VERSION ""

NS_ :

BS_:

BU_: INV BMS VCU

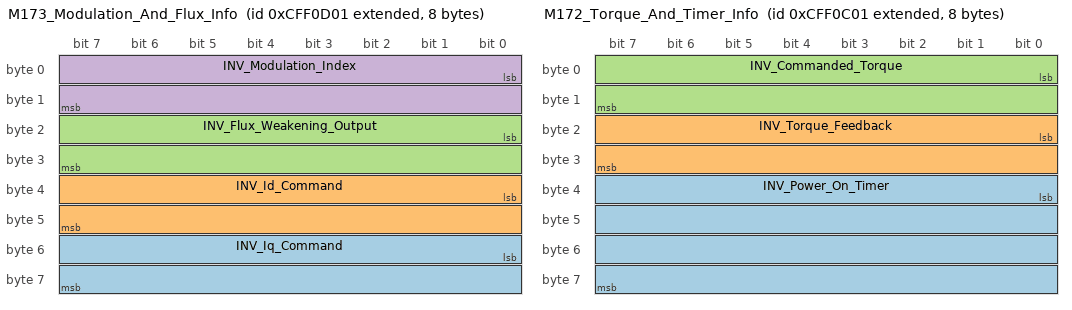
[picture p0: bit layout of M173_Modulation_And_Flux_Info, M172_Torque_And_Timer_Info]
BO_ 2365525249 M173_Modulation_And_Flux_Info: 8 INV
 SG_ INV_Iq_Command : 48|16@1- (0.1,0) [-3276.8|3276.7] "current:A" Vector__XXX
 SG_ INV_Id_Command : 32|16@1- (0.1,0) [-3276.8|3276.7] "current:A" Vector__XXX
 SG_ INV_Flux_Weakening_Output : 16|16@1- (0.1,0) [-3276.8|3276.7] "current:A" Vector__XXX
 SG_ INV_Modulation_Index : 0|16@1- (0.0001,0) [-3.2768|3.2767] "" Vector__XXX

BO_ 2365524993 M172_Torque_And_Timer_Info: 8 INV
 SG_ INV_Power_On_Timer : 32|32@1+ (0.003,0) [0|12884800] "time:second" Vector__XXX
 SG_ INV_Torque_Feedback : 16|16@1- (0.1,0) [-3276.8|3276.7] "torque:N.m" Vector__XXX
 SG_ INV_Commanded_Torque : 0|16@1- (0.1,0) [-3276.8|3276.7] "torque:N.m" Vector__XXX

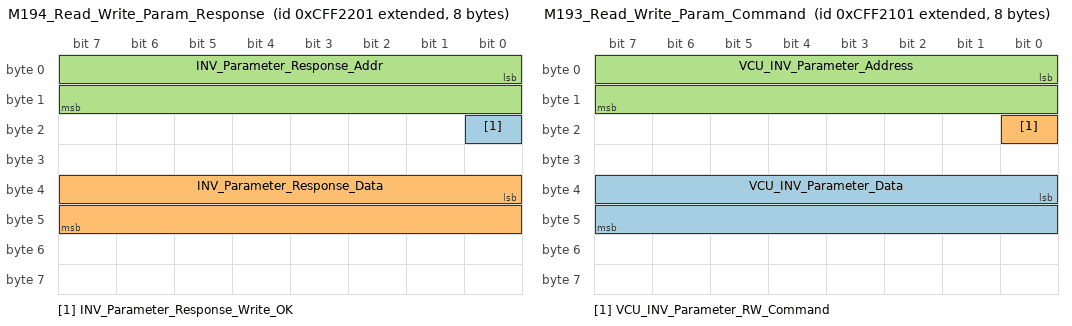
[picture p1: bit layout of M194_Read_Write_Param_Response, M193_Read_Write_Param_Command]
BO_ 2365530625 M194_Read_Write_Param_Response: 8 INV
 SG_ INV_Parameter_Response_Write_OK : 16|1@1+ (1,0) [0|1] "" Vector__XXX
 SG_ INV_Parameter_Response_Data : 32|16@1- (1,0) [-32768|32767] "" Vector__XXX
 SG_ INV_Parameter_Response_Addr : 0|16@1+ (1,0) [0|65535] "" Vector__XXX

BO_ 2365530369 M193_Read_Write_Param_Command: 8 VCU
 SG_ VCU_INV_Parameter_Data : 32|16@1- (1,0) [-32768|32767] "" Vector__XXX
 SG_ VCU_INV_Parameter_RW_Command : 16|1@1+ (1,0) [0|1] "" Vector__XXX
 SG_ VCU_INV_Parameter_Address : 0|16@1+ (1,0) [0|65535] "" Vector__XXX

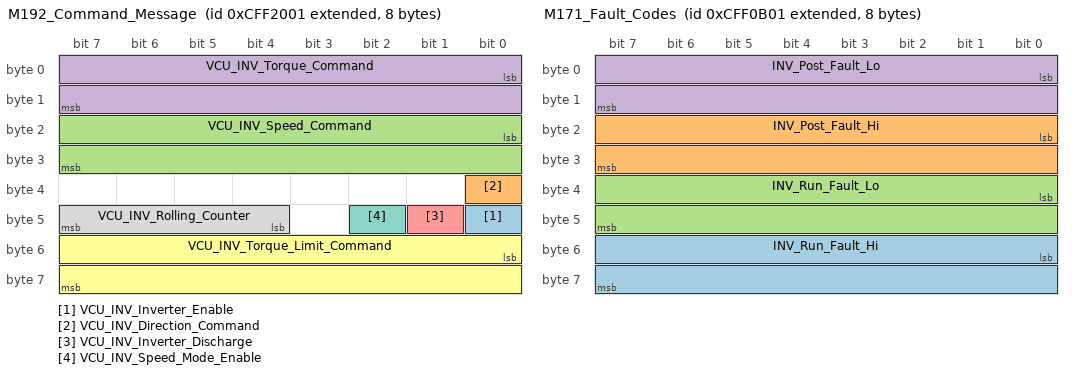
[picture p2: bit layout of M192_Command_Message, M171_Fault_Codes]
BO_ 2365530113 M192_Command_Message: 8 VCU
 SG_ VCU_INV_Inverter_Enable : 40|1@1+ (1,0) [0|1] "" Vector__XXX
 SG_ VCU_INV_Direction_Command : 32|1@1+ (1,0) [0|1] "" Vector__XXX
 SG_ VCU_INV_Speed_Command : 16|16@1- (1,0) [-32768|32767] "angular_speed:rpm" Vector__XXX
 SG_ VCU_INV_Torque_Command : 0|16@1- (0.1,0) [-3276.8|3276.7] "torque:N.m" Vector__XXX
 SG_ VCU_INV_Inverter_Discharge : 41|1@1+ (1,0) [0|1] "" Vector__XXX
 SG_ VCU_INV_Torque_Limit_Command : 48|16@1- (0.1,0) [-3276.8|3276.7] "torque:N.m" Vector__XXX
 SG_ VCU_INV_Speed_Mode_Enable : 42|1@1+ (1,0) [0|1] "" Vector__XXX
 SG_ VCU_INV_Rolling_Counter : 44|4@1+ (1,0) [0|15] "" Vector__XXX

BO_ 2365524737 M171_Fault_Codes: 8 INV
 SG_ INV_Run_Fault_Hi : 48|16@1+ (1,0) [0|65535] "" Vector__XXX
 SG_ INV_Post_Fault_Hi : 16|16@1+ (1,0) [0|65535] "" Vector__XXX
 SG_ INV_Run_Fault_Lo : 32|16@1+ (1,0) [0|65535] "" Vector__XXX
 SG_ INV_Post_Fault_Lo : 0|16@1+ (1,0) [0|65535] "" Vector__XXX

BO_ 2365524481 M170_Internal_States: 8 INV
 SG_ INV_Direction_Command : 56|1@1+ (1,0) [0|1] "" Vector__XXX
 SG_ INV_Inverter_Enable_State : 48|1@1+ (1,0) [0|1] "" Vector__XXX
 SG_ INV_Relay_3_Status : 26|1@1+ (1,0) [0|1] "" Vector__XXX
 SG_ INV_Relay_4_Status : 27|1@1+ (1,0) [0|1] "" Vector__XXX
 SG_ INV_Relay_2_Status : 25|1@1+ (1,0) [0|1] "" Vector__XXX
 SG_ INV_Inverter_Run_Mode : 32|1@1+ (1,0) [0|1] "" Vector__XXX
 SG_ INV_Inverter_Command_Mode : 40|1@1+ (1,0) [0|1] "" Vector__XXX
 SG_ INV_Relay_1_Status : 24|1@1+ (1,0) [0|1] "" Vector__XXX
 SG_ INV_Inverter_State : 16|8@1+ (1,0) [0|255] "" Vector__XXX
 SG_ INV_VSM_State : 0|8@1+ (1,0) [0|15] "" Vector__XXX
 SG_ INV_Inverter_Enable_Lockout : 55|1@1+ (1,0) [0|1] "" Vector__XXX
 SG_ INV_Inverter_Discharge_State : 37|3@1+ (1,0) [0|7] "" Vector__XXX
 SG_ INV_Relay_5_Status : 28|1@1+ (1,0) [0|1] "" Vector__XXX
 SG_ INV_Relay_6_Status : 29|1@1+ (1,0) [0|1] "" Vector__XXX
 SG_ INV_BMS_Active : 57|1@1+ (1,0) [0|1] "" Vector__XXX
 SG_ INV_BMS_Limiting_Motor_Torque : 58|1@1+ (1,0) [0|1] "" Vector__XXX
 SG_ INV_PWM_Frequency : 8|8@1+ (1,0) [0|255] "" Vector__XXX
 SG_ INV_Limit_Max_Speed : 59|1@1+ (1,0) [0|1] "" Vector__XXX
 SG_ INV_Limit_Hot_Spot_Inverter : 60|1@1+ (1,0) [0|1] "" Vector__XXX
 SG_ INV_Low_Speed_Limiting : 61|1@1+ (1,0) [0|1] "" Vector__XXX
 SG_ INV_Rolling_Counter : 44|4@1+ (1,0) [0|15] "" Vector__XXX
 SG_ INV_Limit_Coolant_Derating : 62|1@1+ (1,0) [0|1] "" Vector__XXX
 SG_ INV_Self_Sensing_Assist_Enable : 33|1@1+ (1,0) [0|1] "" Vector__XXX
 SG_ INV_Limit_Stall_Burst_Model : 63|1@1+ (1,0) [0|1] "" Vector__XXX
 SG_ INV_Burst_Model_Mode : 49|1@1+ (1,0) [0|1] "" Vector__XXX
 SG_ INV_Key_Switch_Start_Status : 54|1@1+ (1,0) [0|1] "" Vector__XXX
 SG_ INV_BMS_Limiting_Regen_Torque : 50|1@1+ (1,0) [0|0] "" Vector__XXX
 SG_ INV_Limit_Motor_Temp_Derate : 52|1@1+ (1,0) [0|0] "" Vector__XXX
 SG_ INV_Limit_Hot_Spot_Motor : 53|1@1+ (1,0) [0|0] "" Vector__XXX
 SG_ INV_ASC_State : 34|3@1+ (1,0) [0|0] "" Vector__XXX

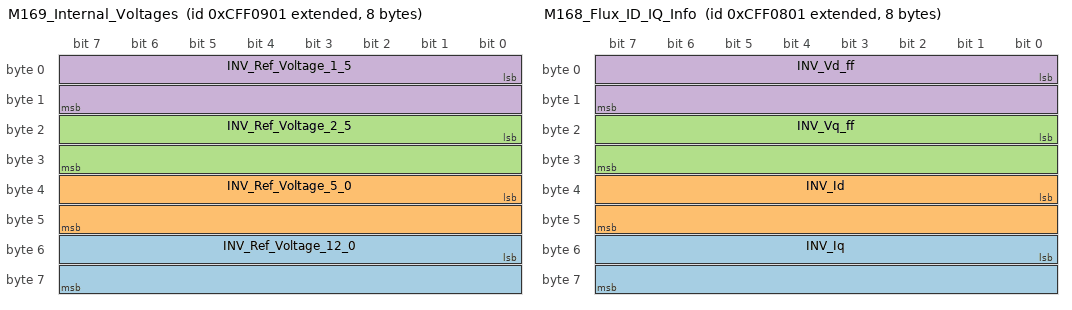
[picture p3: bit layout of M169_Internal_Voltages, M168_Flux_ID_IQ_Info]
BO_ 2365524225 M169_Internal_Voltages: 8 INV
 SG_ INV_Ref_Voltage_12_0 : 48|16@1- (0.01,0) [-327.68|327.67] "voltage:V" Vector__XXX
 SG_ INV_Ref_Voltage_5_0 : 32|16@1- (0.01,0) [-327.68|327.67] "voltage:V" Vector__XXX
 SG_ INV_Ref_Voltage_2_5 : 16|16@1- (0.01,0) [-327.68|327.67] "voltage:V" Vector__XXX
 SG_ INV_Ref_Voltage_1_5 : 0|16@1- (0.01,0) [-327.68|327.67] "voltage:V" Vector__XXX

BO_ 2365523969 M168_Flux_ID_IQ_Info: 8 INV
 SG_ INV_Iq : 48|16@1- (0.1,0) [-3276.8|3276.7] "current:A" Vector__XXX
 SG_ INV_Id : 32|16@1- (0.1,0) [-3276.8|3276.7] "current:A" Vector__XXX
 SG_ INV_Vq_ff : 16|16@1- (0.1,0) [-3276.7|3276.7] "voltage:V" Vector__XXX
 SG_ INV_Vd_ff : 0|16@1- (0.1,0) [-3276.7|3276.7] "voltage:V" Vector__XXX

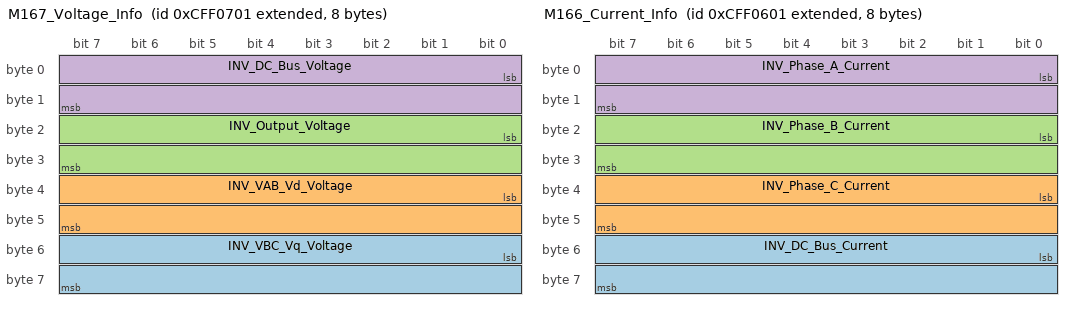
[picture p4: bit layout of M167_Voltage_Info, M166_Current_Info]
BO_ 2365523713 M167_Voltage_Info: 8 INV
 SG_ INV_VBC_Vq_Voltage : 48|16@1- (0.1,0) [-3276.8|3276.7] "voltage:V" Vector__XXX
 SG_ INV_VAB_Vd_Voltage : 32|16@1- (0.1,0) [-3276.8|3276.7] "voltage:V" Vector__XXX
 SG_ INV_Output_Voltage : 16|16@1- (0.1,0) [-3276.8|3276.7] "voltage:V" Vector__XXX
 SG_ INV_DC_Bus_Voltage : 0|16@1- (0.1,0) [-3276.8|3276.7] "voltage:V" Vector__XXX

BO_ 2365523457 M166_Current_Info: 8 INV
 SG_ INV_DC_Bus_Current : 48|16@1- (0.1,0) [-3276.8|3276.7] "current:A" Vector__XXX
 SG_ INV_Phase_C_Current : 32|16@1- (0.1,0) [-3276.8|3276.7] "current:A" Vector__XXX
 SG_ INV_Phase_B_Current : 16|16@1- (0.1,0) [-3276.8|3276.7] "current:A" Vector__XXX
 SG_ INV_Phase_A_Current : 0|16@1- (0.1,0) [-3276.8|3276.7] "current:A" Vector__XXX

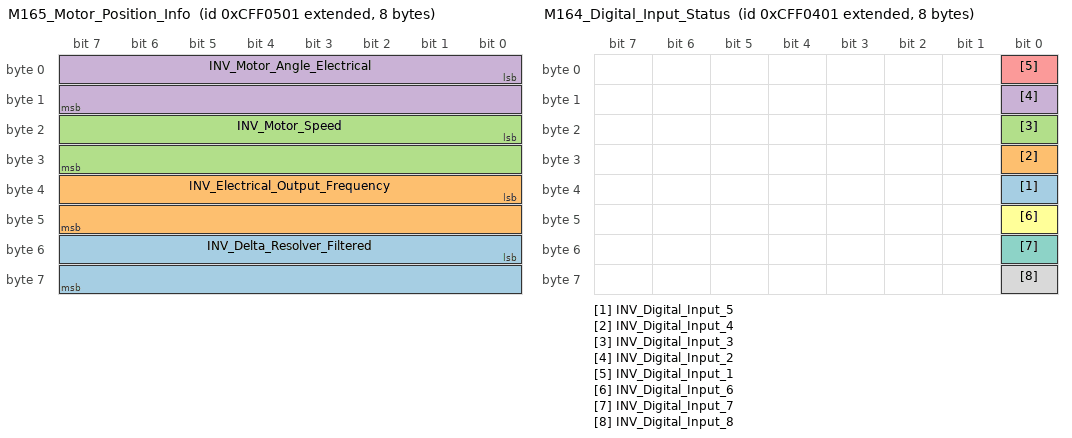
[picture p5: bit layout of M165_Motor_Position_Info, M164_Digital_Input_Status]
BO_ 2365523201 M165_Motor_Position_Info: 8 INV
 SG_ INV_Delta_Resolver_Filtered : 48|16@1- (0.1,0) [-3276.8|3276.7] "angle:deg" Vector__XXX
 SG_ INV_Electrical_Output_Frequency : 32|16@1- (0.1,0) [-3276.8|3276.7] "frequency:Hz" Vector__XXX
 SG_ INV_Motor_Speed : 16|16@1- (1,0) [-32768|32767] "angular_speed:rpm" Vector__XXX
 SG_ INV_Motor_Angle_Electrical : 0|16@1+ (0.1,0) [0|6553.5] "angle:deg" Vector__XXX

BO_ 2365522945 M164_Digital_Input_Status: 8 INV
 SG_ INV_Digital_Input_5 : 32|1@1+ (1,0) [0|1] "" Vector__XXX
 SG_ INV_Digital_Input_4 : 24|1@1+ (1,0) [0|1] "" Vector__XXX
 SG_ INV_Digital_Input_3 : 16|1@1+ (1,0) [0|1] "" Vector__XXX
 SG_ INV_Digital_Input_2 : 8|1@1+ (1,0) [0|1] "" Vector__XXX
 SG_ INV_Digital_Input_1 : 0|1@1+ (1,0) [0|1] "" Vector__XXX
 SG_ INV_Digital_Input_6 : 40|1@1+ (1,0) [0|1] "" Vector__XXX
 SG_ INV_Digital_Input_7 : 48|1@1+ (1,0) [0|1] "" Vector__XXX
 SG_ INV_Digital_Input_8 : 56|1@1+ (1,0) [0|1] "" Vector__XXX

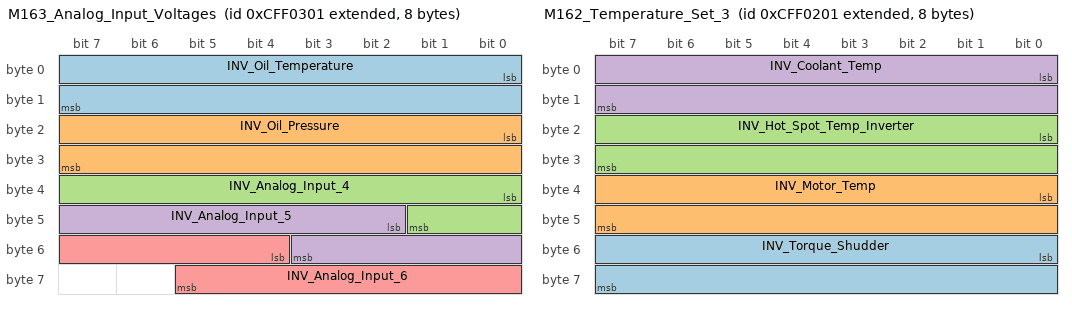
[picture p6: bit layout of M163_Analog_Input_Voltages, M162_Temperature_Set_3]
BO_ 2365522689 M163_Analog_Input_Voltages: 8 INV
 SG_ INV_Oil_Temperature : 0|16@1- (0.1,0) [-3276.8|3276.7] "temperature:C" Vector__XXX
 SG_ INV_Oil_Pressure : 16|16@1- (0.1,0) [-3276.8|3276.7] "pressure:psi" Vector__XXX
 SG_ INV_Analog_Input_4 : 32|10@1+ (0.01,0) [0|10.23] "voltage:V" Vector__XXX
 SG_ INV_Analog_Input_5 : 42|10@1+ (0.01,0) [0|10.23] "voltage:V" Vector__XXX
 SG_ INV_Analog_Input_6 : 52|10@1+ (0.01,0) [0|10.23] "voltage:V" Vector__XXX

BO_ 2365522433 M162_Temperature_Set_3: 8 INV
 SG_ INV_Torque_Shudder : 48|16@1- (0.1,0) [-3276.8|3276.7] "torque:N.m" Vector__XXX
 SG_ INV_Motor_Temp : 32|16@1- (0.1,0) [-3276.8|3276.7] "temperature:C" Vector__XXX
 SG_ INV_Hot_Spot_Temp_Inverter : 16|16@1- (0.1,0) [-3276.8|3276.7] "temperature:C" Vector__XXX
 SG_ INV_Coolant_Temp : 0|16@1- (0.1,0) [-3276.8|3276.7] "temperature:C" Vector__XXX

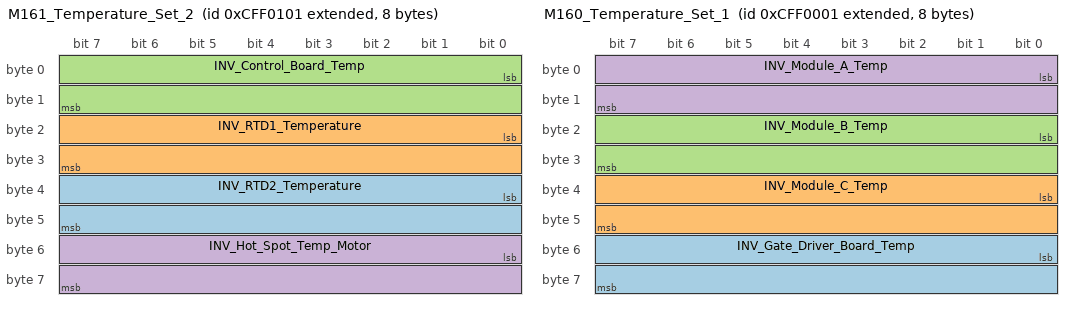
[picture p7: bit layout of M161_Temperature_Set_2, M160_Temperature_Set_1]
BO_ 2365522177 M161_Temperature_Set_2: 8 INV
 SG_ INV_RTD2_Temperature : 32|16@1- (0.1,0) [-3276.8|3276.7] "temperature:C" Vector__XXX
 SG_ INV_RTD1_Temperature : 16|16@1- (0.1,0) [-3276.8|3276.7] "temperature:C" Vector__XXX
 SG_ INV_Control_Board_Temp : 0|16@1- (0.1,0) [-3276.8|3276.7] "temperature:C" Vector__XXX
 SG_ INV_Hot_Spot_Temp_Motor : 48|16@1- (0.1,0) [-3276.8|3276.7] "temperature:C" Vector__XXX

BO_ 2365521921 M160_Temperature_Set_1: 8 INV
 SG_ INV_Gate_Driver_Board_Temp : 48|16@1- (0.1,0) [-3276.8|3276.7] "temperature:C" Vector__XXX
 SG_ INV_Module_C_Temp : 32|16@1- (0.1,0) [-3276.8|3276.7] "temperature:C" Vector__XXX
 SG_ INV_Module_B_Temp : 16|16@1- (0.1,0) [-3276.8|3276.7] "temperature:C" Vector__XXX
 SG_ INV_Module_A_Temp : 0|16@1- (0.1,0) [-3276.8|3276.7] "temperature:C" Vector__XXX

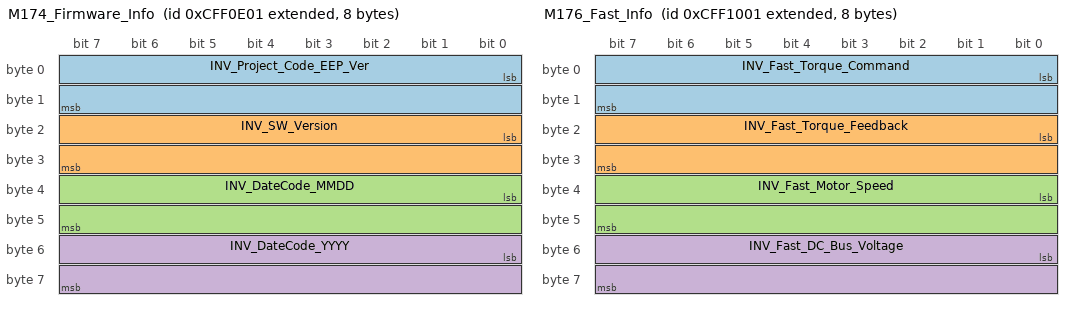
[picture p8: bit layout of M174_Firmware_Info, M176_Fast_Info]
BO_ 2365525505 M174_Firmware_Info: 8 INV
 SG_ INV_Project_Code_EEP_Ver : 0|16@1+ (1,0) [0|65535] "" Vector__XXX
 SG_ INV_SW_Version : 16|16@1+ (1,0) [0|65535] "" Vector__XXX
 SG_ INV_DateCode_MMDD : 32|16@1+ (1,0) [0|65535] "" Vector__XXX
 SG_ INV_DateCode_YYYY : 48|16@1+ (1,0) [0|65535] "" Vector__XXX

BO_ 2365525761 M175_Diag_Data_Message: 8 INV
 SG_ INV_Diag_Record : 0|8@1+ (1,0) [0|160] "" Vector__XXX
 SG_ INV_Diag_Segment M : 8|8@1+ (1,0) [0|5] "" Vector__XXX
 SG_ INV_Diag_Gamma_Resolver m0 : 16|16@1- (0.1,0) [0|360] "angle:deg" Vector__XXX
 SG_ INV_Diag_Gamma_Observer m0 : 32|16@1- (0.1,0) [0|360] "angle:deg" Vector__XXX
 SG_ INV_Diag_Sin_Used m0 : 48|16@1- (1,0) [-5|5] "voltage:V" Vector__XXX
 SG_ INV_Diag_Cos_Used m1 : 16|16@1- (1,0) [-5|5] "voltage:V" Vector__XXX
 SG_ INV_Diag_Ia m1 : 32|16@1- (0.1,0) [-2000|2000] "current:A" Vector__XXX
 SG_ INV_Diag_Ib m1 : 48|16@1- (0.1,0) [-2000|2000] "current:A" Vector__XXX
 SG_ INV_Diag_Ic m2 : 16|16@1- (0.1,0) [-2000|2000] "current:A" Vector__XXX
 SG_ INV_Diag_Vdc m2 : 32|16@1- (0.1,0) [0|1000] "voltage:V" Vector__XXX
 SG_ INV_Diag_Iq_cmd m2 : 48|16@1- (0.1,0) [-2000|2000] "current:A" Vector__XXX
 SG_ INV_Diag_Id_cmd m3 : 16|16@1- (0.1,0) [-2000|2000] "current:A" Vector__XXX
 SG_ INV_Diag_Mod_Index m3 : 32|16@1- (0.0001,0) [0|2] "" Vector__XXX
 SG_ INV_Diag_FW_Output m3 : 48|16@1- (0.1,0) [-2000|2000] "current:A" Vector__XXX
 SG_ INV_Diag_Vq_Cmd m4 : 16|16@1- (0.1,0) [-1000|1000] "voltage:V" Vector__XXX
 SG_ INV_Diag_Vd_Cmd m4 : 32|16@1- (0.1,0) [-1000|1000] "voltage:V" Vector__XXX
 SG_ INV_Diag_Vqs_Cmd m4 : 48|16@1- (0.1,0) [-1000|1000] "voltage:V" Vector__XXX
 SG_ INV_Diag_PWM_Freq m5 : 16|16@1+ (1,0) [0|24] "frequency:kHz" Vector__XXX
 SG_ INV_Diag_Run_Faults_Lo m5 : 32|16@1+ (1,0) [0|65535] "" Vector__XXX
 SG_ INV_Diag_Run_Faults_Hi m5 : 48|16@1+ (1,0) [0|65535] "" Vector__XXX

BO_ 514 BMS_Current_Limit: 8 BMS
 SG_ BMS_Max_Discharge_Current : 0|16@1+ (1,0) [0|1000] "current:A" Vector__XXX
 SG_ BMS_Max_Charge_Current : 16|16@1+ (1,0) [0|1000] "current:A" Vector__XXX

BO_ 2365526017 M176_Fast_Info: 8 INV
 SG_ INV_Fast_Torque_Command : 0|16@1- (0.1,0) [-3276.8|32767.7] "torque:N.m" Vector__XXX
 SG_ INV_Fast_Torque_Feedback : 16|16@1- (0.1,0) [-3276.8|3276.7] "torque:N.m" Vector__XXX
 SG_ INV_Fast_Motor_Speed : 32|16@1- (1,0) [-32768|32767] "angular_speed:rpm" Vector__XXX
 SG_ INV_Fast_DC_Bus_Voltage : 48|16@1- (0.1,0) [-3276.8|3276.7] "voltage:V" Vector__XXX

BO_ 2365526273 M177_Torque_Capability: 8 INV
 SG_ INV_Torque_Capability_Motor : 0|16@1- (0.1,0) [0|3276.7] "torque:N.m" Vector__XXX
 SG_ INV_Torque_Capability_Regen : 16|16@1- (0.1,0) [-3276.8|0] "torque:N.m" Vector__XXX

CM_ SG_ 2365525249 INV_Iq_Command "The commanded Q-axis current";
CM_ SG_ 2365525249 INV_Id_Command "The commanded D-axis current";
CM_ SG_ 2365525249 INV_Flux_Weakening_Output "This is the current output of the flux regulator.";
CM_ SG_ 2365525249 INV_Modulation_Index "This is the modulation index. The scale factor is x100. To get the actual modulation index divide the value by 100.";
CM_ SG_ 2365524993 INV_Power_On_Timer "Updated every 3 msec. This will roll over in approximately 150 days!";
CM_ SG_ 2365524993 INV_Torque_Feedback "Estimated motor torque feedback";
CM_ SG_ 2365524993 INV_Commanded_Torque "The commanded Torque";
CM_ BO_ 2365530625 "To write a parameter use message 0x0C1 with byte #2 set to 1 (write). 
To read a parameter use message 0x0C1 with byte #2 to set 0 (read). ";
CM_ SG_ 2365530625 INV_Parameter_Response_Write_OK "0=Write failure, 1=Success";
CM_ SG_ 2365530625 INV_Parameter_Response_Data "Data from parameter message.  All data is 16 bits and is contained in bytes 4 and 5. Bytes 6 and 7 should be ignored.";
CM_ SG_ 2365530625 INV_Parameter_Response_Addr "Address of parameter response message data.";
CM_ BO_ 2365530369 "To write a parameter use message 0x0C1 with byte #2 set to 1 (write). 
To read a parameter use message 0x0C1 with byte #2 to set 0 (read). ";
CM_ SG_ 2365530369 VCU_INV_Parameter_Data "Data to be written.  All data is 16 bits and is contained in bytes 4 and 5.";
CM_ SG_ 2365530369 VCU_INV_Parameter_RW_Command "0=Read, 1=Write";
CM_ SG_ 2365530369 VCU_INV_Parameter_Address "Address of parameter to be written or read.";
CM_ BO_ 2365530113 "The command message is used to transmit data to the controller. This message is sent from a user supplied external controller to the PMxxx controller.";
CM_ SG_ 2365530113 VCU_INV_Inverter_Enable "0=Inverter OFF, 1 = Inverter ON";
CM_ SG_ 2365530113 VCU_INV_Direction_Command "0=Reverse, 1=Forward.  Forward is positive motor speed.";
CM_ SG_ 2365530113 VCU_INV_Speed_Command "Speed command used when in speed mode";
CM_ SG_ 2365530113 VCU_INV_Torque_Command "Torque command when in torque mode";
CM_ SG_ 2365530113 VCU_INV_Inverter_Discharge "0=Discharge Disable,1=Discharge Enable";
CM_ SG_ 2365530113 VCU_INV_Torque_Limit_Command "Torque Limit, set to 0 to keep default";
CM_ SG_ 2365530113 VCU_INV_Speed_Mode_Enable "0 = No change to mode, 1 = change to speed mode from torque mode";
CM_ SG_ 2365530113 VCU_INV_Rolling_Counter "Rolling Counter sent to inverter.  If used increment count with each message sent.  Otherwise can be set to 0.";
CM_ SG_ 2365524737 INV_Run_Fault_Hi "Each bit represents a fault. Please refer to PM100 Users Manual for details.";
CM_ SG_ 2365524737 INV_Post_Fault_Hi "Each bit represents a fault. Please refer to PM100 Users Manual for details.";
CM_ SG_ 2365524737 INV_Run_Fault_Lo "Each bit represents a fault. Please refer to PM100 Users Manual for details.";
CM_ SG_ 2365524737 INV_Post_Fault_Lo "Each bit represents a fault. Please refer to PM100 Users Manual for details.";
CM_ SG_ 2365524481 INV_Direction_Command "1 = Forward
0 = 'Reverse' if inverter enabled  & 'Stopped' if inverter is disabled";
CM_ SG_ 2365524481 INV_Inverter_Enable_State "0=Inverter Disabled, 
1=Inverter Enabled";
CM_ SG_ 2365524481 INV_Relay_3_Status "0=OFF, 1=ON";
CM_ SG_ 2365524481 INV_Relay_4_Status "0=OFF, 1=ON";
CM_ SG_ 2365524481 INV_Relay_2_Status "0=OFF, 1=ON";
CM_ SG_ 2365524481 INV_Inverter_Run_Mode "0=Torque Mode, 1=Speed Mode";
CM_ SG_ 2365524481 INV_Inverter_Command_Mode "0=CAN mode, 1=VSM mode";
CM_ SG_ 2365524481 INV_Relay_1_Status "0=OFF, 1=ON";
CM_ SG_ 2365524481 INV_Inverter_State "Different states for the inverter state machine";
CM_ SG_ 2365524481 INV_VSM_State "Different states for the vehicle state machine";
CM_ SG_ 2365524481 INV_Inverter_Enable_Lockout "0=Lockout Disabled, 1=Lockout Enabled";
CM_ SG_ 2365524481 INV_Inverter_Discharge_State "0 = Disabled, 1 = Enabled, 2 = Speed Check, 3 = Active, 4 = Complete";
CM_ SG_ 2365524481 INV_Relay_5_Status "0=OFF, 1=ON";
CM_ SG_ 2365524481 INV_Relay_6_Status "0=OFF, 1=ON";
CM_ SG_ 2365524481 INV_BMS_Active "0 = BMS Not Active, 1 = BMS Active";
CM_ SG_ 2365524481 INV_BMS_Limiting_Motor_Torque "0 = Not Limiting, 1 = Limiting";
CM_ SG_ 2365524481 INV_PWM_Frequency "The current active PWM frequency";
CM_ SG_ 2365524481 INV_Limit_Max_Speed "Indicates that torque is being modified to limit the speed.";
CM_ SG_ 2365524481 INV_Limit_Hot_Spot_Inverter "Indicates that torque is being limited to limit the inverter hot spot temp";
CM_ SG_ 2365524481 INV_Low_Speed_Limiting "Indicates that motor current is being limited due to low motor electrical frequency.";
CM_ SG_ 2365524481 INV_Rolling_Counter "Rolling Counter value";
CM_ SG_ 2365524481 INV_Limit_Coolant_Derating "0 = Not limiting, 1 = Limiting";
CM_ SG_ 2365524481 INV_Self_Sensing_Assist_Enable "1 = Self Sensing Assist Enabled, 0 = Self Sensing Assist Disabled";
CM_ SG_ 2365524481 INV_Limit_Stall_Burst_Model "0 = Not limiting, 1 = Limiting";
CM_ SG_ 2365524481 INV_Burst_Model_Mode "0 = Stall, 1 = High Speed";
CM_ SG_ 2365524481 INV_Key_Switch_Start_Status "0 = OFF, 1 = ON";
CM_ SG_ 2365524481 INV_BMS_Limiting_Regen_Torque "0 = Not Limiting, 1 = Limiting";
CM_ SG_ 2365524481 INV_Limit_Motor_Temp_Derate "Indicates that torque is being limited to limit the motor temperature, based on Full Torque and Zero Torque temperature EEPROM values.";
CM_ SG_ 2365524481 INV_Limit_Hot_Spot_Motor "Indicates that torque is being limited to limit the motor hot spot temp";
CM_ SG_ 2365524481 INV_ASC_State "Active Short Circuit State";
CM_ SG_ 2365524225 INV_Ref_Voltage_12_0 "12V Input Voltage";
CM_ SG_ 2365524225 INV_Ref_Voltage_5_0 "Transducer voltage";
CM_ SG_ 2365524225 INV_Ref_Voltage_2_5 "Internal reference voltage";
CM_ SG_ 2365524225 INV_Ref_Voltage_1_5 "Internal reference voltage";
CM_ SG_ 2365523969 INV_Iq "The measured Iq current";
CM_ SG_ 2365523969 INV_Id "The measured Id current";
CM_ SG_ 2365523969 INV_Vq_ff "The q-axis voltage feedforward";
CM_ SG_ 2365523969 INV_Vd_ff "The d-axis voltage feedforward";
CM_ SG_ 2365523713 INV_VBC_Vq_Voltage "Measured value of the voltage between Phase B and Phase C";
CM_ SG_ 2365523713 INV_VAB_Vd_Voltage "Measured value of the voltage betwen phase A and Phase B";
CM_ SG_ 2365523713 INV_Output_Voltage "The calculated value of the output voltage, in peak line-neutral volts";
CM_ SG_ 2365523713 INV_DC_Bus_Voltage "The actual measured value of the DC bus voltage";
CM_ SG_ 2365523457 INV_DC_Bus_Current "The Calculated DC Bus Current";
CM_ SG_ 2365523457 INV_Phase_C_Current "The measured value of Phase C current";
CM_ SG_ 2365523457 INV_Phase_B_Current "The measured value of Phase B current";
CM_ SG_ 2365523457 INV_Phase_A_Current "The measured value of Phase A current";
CM_ SG_ 2365523201 INV_Delta_Resolver_Filtered "Used in calibration of resolver angle adjustment.";
CM_ SG_ 2365523201 INV_Electrical_Output_Frequency "The actual electrical frequency of the inverter";
CM_ SG_ 2365523201 INV_Motor_Speed "The measured speed of the motor";
CM_ SG_ 2365523201 INV_Motor_Angle_Electrical "The Electrical Angle of the motor as read by the encoder or resolver";
CM_ SG_ 2365522945 INV_Digital_Input_5 "Status of Digital Input #5";
CM_ SG_ 2365522945 INV_Digital_Input_4 "Status of Digital Input #4";
CM_ SG_ 2365522945 INV_Digital_Input_3 "Status of Digital Input #3";
CM_ SG_ 2365522945 INV_Digital_Input_2 "Status of Digital Input #2";
CM_ SG_ 2365522945 INV_Digital_Input_1 "Status of Digital Input #1";
CM_ SG_ 2365522945 INV_Digital_Input_6 "Status of Digital Input #6";
CM_ SG_ 2365522945 INV_Digital_Input_7 "Status of Digital Input #7";
CM_ SG_ 2365522945 INV_Digital_Input_8 "Status of Digital Input #8";
CM_ SG_ 2365522689 INV_Oil_Temperature "Oil Temperature from sensor on motor assembly";
CM_ SG_ 2365522689 INV_Oil_Pressure "Oil Temperature from sensor on motor assembly";
CM_ SG_ 2365522689 INV_Analog_Input_4 "Voltage on Analog Input #4";
CM_ SG_ 2365522689 INV_Analog_Input_5 "Voltage on Analog Input #5";
CM_ SG_ 2365522689 INV_Analog_Input_6 "Voltage on Analog Input #6";
CM_ SG_ 2365522433 INV_Torque_Shudder "Shudder compensation value of torque";
CM_ SG_ 2365522433 INV_Motor_Temp "Motor Temperature Sensor";
CM_ SG_ 2365522433 INV_Hot_Spot_Temp_Inverter "Estimated inverter hot spot temperature";
CM_ SG_ 2365522433 INV_Coolant_Temp "Estimated Coolant Temperature";
CM_ SG_ 2365522177 INV_RTD2_Temperature "RTD input 2 (PT1000) Temperature";
CM_ SG_ 2365522177 INV_RTD1_Temperature "RTD input 1 (PT1000) Temperature";
CM_ SG_ 2365522177 INV_Control_Board_Temp "Control Board Temperature";
CM_ SG_ 2365522177 INV_Hot_Spot_Temp_Motor "Estimated motor hot spot temperature";
CM_ SG_ 2365521921 INV_Gate_Driver_Board_Temp "Gate Driver Board Temperature";
CM_ SG_ 2365521921 INV_Module_C_Temp "IGBT Module C Temperature";
CM_ SG_ 2365521921 INV_Module_B_Temp "IGBT Module B Temperature";
CM_ SG_ 2365521921 INV_Module_A_Temp "IGBT Module A Temperature";
CM_ BO_ 514 "Sent by BMS";
CM_ SG_ 514 BMS_Max_Discharge_Current "Maximum discharge current from BMS";
CM_ SG_ 514 BMS_Max_Charge_Current "Maximum charge current from BMS";
CM_ BO_ 2365526017 "To enable fast message set CAN ACTIVE MSGS HI WORD to 0xFFFE.  Setting to default value of 0xFFFF will disable the fast message.";
CM_ SG_ 2365526017 INV_Fast_Torque_Command "The commanded torque";
CM_ SG_ 2365526017 INV_Fast_Torque_Feedback "The estimated torque";
CM_ SG_ 2365526017 INV_Fast_Motor_Speed "Motor speed";
CM_ SG_ 2365526017 INV_Fast_DC_Bus_Voltage "DC Bus Voltage";
CM_ SG_ 2365526273 INV_Torque_Capability_Motor "The motoring torque capability of the inverter given the current operating point.";
CM_ SG_ 2365526273 INV_Torque_Capability_Regen "The regen torque capability of the inverter given the current operating point.";
BA_DEF_ BO_  "GenMsgCycleTime" INT 0 100000;
BA_DEF_  "BusType" STRING ;
BA_DEF_DEF_  "GenMsgCycleTime" 0;
BA_DEF_DEF_  "BusType" "CAN";
BA_ "GenMsgCycleTime" BO_ 2365525249 10;
BA_ "GenMsgCycleTime" BO_ 2365524993 10;
BA_ "GenMsgCycleTime" BO_ 2365530113 10;
BA_ "GenMsgCycleTime" BO_ 2365524737 10;
BA_ "GenMsgCycleTime" BO_ 2365524481 10;
BA_ "GenMsgCycleTime" BO_ 2365524225 100;
BA_ "GenMsgCycleTime" BO_ 2365523969 10;
BA_ "GenMsgCycleTime" BO_ 2365523713 10;
BA_ "GenMsgCycleTime" BO_ 2365523457 10;
BA_ "GenMsgCycleTime" BO_ 2365523201 10;
BA_ "GenMsgCycleTime" BO_ 2365522945 10;
BA_ "GenMsgCycleTime" BO_ 2365522689 10;
BA_ "GenMsgCycleTime" BO_ 2365522433 100;
BA_ "GenMsgCycleTime" BO_ 2365522177 100;
BA_ "GenMsgCycleTime" BO_ 2365521921 100;
BA_ "GenMsgCycleTime" BO_ 2365525505 100;
BA_ "GenMsgCycleTime" BO_ 2365525761 10;
BA_ "GenMsgCycleTime" BO_ 2365526017 3;
BA_ "GenMsgCycleTime" BO_ 2365526273 10;
VAL_ 2365530113 VCU_INV_Inverter_Enable 0 "Turn the inverter OFF" 1 "Turn the Inverter ON" ;
VAL_ 2365530113 VCU_INV_Direction_Command 0 "CW" 1 "CCW" ;
VAL_ 2365530113 VCU_INV_Inverter_Discharge 0 "Discharge Disable" 1 "Discharge Enable (if EEPROM parameter is set)" ;
VAL_ 2365524481 INV_Inverter_State 0 "Power up" 1 "Stop" 2 "Open Loop" 3 "Closed Loop" 4 "Internal State" 5 "Internal State" 6 "Internal State" 7 "Internal State" 8 "Idle Run" 9 "Idle Stop" 10 "Internal State" 11 "Intern State" 12 "Internal State" ;
VAL_ 2365524481 INV_VSM_State 0 "VSM Start State" 1 "Pre-Charge Init state" 2 "pre-charge active state" 3 "pre-charge complete state" 4 "VSM wait state" 5 "VSM ready state" 6 "Motor Running State" 7 "blink fault code state" 14 "Shutdown state for Key Switch Mode 1" 15 "Reset the inverter" ;
VAL_ 2365524481 INV_Inverter_Discharge_State 0 "Disabled" 1 "Enabled" 2 "Speed Check" 3 "Active" 4 "Complete" 5 "Error" 6 "Override" 7 "Timeout" ;
VAL_ 2365524481 INV_Limit_Stall_Burst_Model 0 "Not Limiting" 1 "Limiting" ;
VAL_ 2365524481 INV_Burst_Model_Mode 0 "Stall" 1 "High Speed" ;
VAL_ 2365524481 INV_ASC_State 0 "ASC_Disabled" 1 "ASC_Enabled" 2 "ASC_Pending" 3 "ASC_Delay" 4 "ASC_Active" 5 "ASC_Complete" 6 "ASC_Blocked" 7 "ASC_Suppressed" ;
